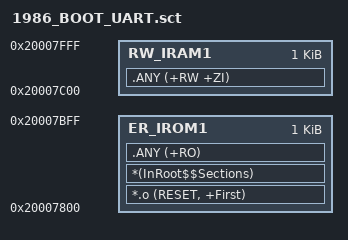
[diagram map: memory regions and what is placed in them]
; *************************************************************
; *** Scatter-Loading Description File generated by uVision ***
; *************************************************************

LR_IROM1 0x20007800 0x00000400  {    ; load region size_region
  ER_IROM1 0x20007800 0x00000400  {  ; load address = execution address
   *.o (RESET, +First)
   *(InRoot$$Sections)
   .ANY (+RO)
  }
  RW_IRAM1 0x20007C00 0x00000400  {  ; RW data
   .ANY (+RW +ZI)
  }
}

